VERSION "ZephyrECU CI fixtures"
NS_ :

BS_:
BU_: ECU Tester

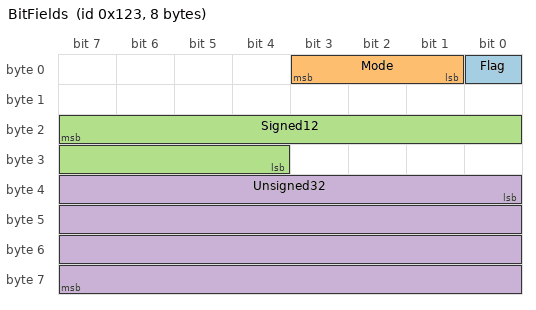
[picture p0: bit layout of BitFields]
BO_ 291 BitFields: 8 Tester
 SG_ Flag : 0|1@1+ (1,0) [0|1] "" ECU
 SG_ Mode : 1|3@1+ (1,0) [0|7] "" ECU
 SG_ Signed12 : 23|12@0- (0.5,-10) [-1034|1013.5] "degC" ECU
 SG_ Unsigned32 : 32|32@1+ (1,0) [0|4294967295] "" ECU

BO_ 2566848769 ExtendedStatus: 8 ECU
 SG_ Counter : 0|32@1+ (1,0) [0|4294967295] "" Tester
 SG_ Torque : 39|12@0- (0.25,0) [-512|511.75] "Nm" Tester

BO_ 512 TriggeredStatus: 2 ECU
 SG_ Changed : 0|8@1+ (1,0) [0|255] "" Tester
 SG_ Pending : 8|8@1+ (1,0) [0|255] "" Tester
